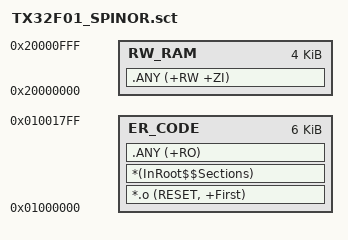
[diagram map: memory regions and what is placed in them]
; APP_SPINOR scatter
;
; This is a STANDALONE app: it owns the reset vector at 0x01000000.
; No bootloader, no soft-vector indirection. The vendor's
; startup_TX32F01.s places the Cortex-M0 vector table at the start of
; the RO image, so as long as ER_CODE begins at 0x01000000 everything
; just works.
;
;   Flash 32 KB total:
;     0x01000000 .. 0x010017FF   code + RO data       (6 KB)
;     0x01001800 .. 0x010077FF   host-visible NOR     (24 KB; managed by spinor_storage.c)
;     0x01007800 .. 0x01007FFF   reserved             (2 KB)
;
;   SRAM 4 KB:
;     0x20000000 .. 0x20000FFF   RW/ZI + stack        (no BL soft-vector reservation here)

LR_SPINOR 0x01000000 0x00001800  {
  ER_CODE 0x01000000 0x00001800  {
    *.o (RESET, +First)
    *(InRoot$$Sections)
    .ANY (+RO)
  }
  RW_RAM 0x20000000 0x00001000  {
    .ANY (+RW +ZI)
  }
}
